AUTOSAR XML (schema 4.0)
standard types defined: float32, float64, sint16, sint32, sint8, uint16, uint32, uint8, void, boolean
package /ImplDataTypes
  5 x impl type, all with category=TYPE_REFERENCE, type-emitter=RTE:
    MultiStateBtnType: implementation-data-type=uint8
    SeatCtrlData_Height: implementation-data-type=uint8
    SeatCtrlData_Incline: implementation-data-type=void
    SeatCtrlData_Slide: implementation-data-type=uint8
    StepMotorStepType: implementation-data-type=uint8
package /MappingSets
  data type mapping set MappingSet
package /PortInterfaces/ClientServer
  client server interface CsIf_StepMotor
    operation Opr_Move
      arg step: type=StepMotorStepType, direction=IN
package /PortInterfaces/SenderReceiver
  sender receiver interface SrIf_SeatCtrlBtns
    data DE_HeightBtnState: type=MultiStateBtnType
    data DE_InclineBtnState: type=MultiStateBtnType
    data DE_SlideBtnState: type=MultiStateBtnType
  sender receiver interface SrIf_SeatCtrlData
    data DE_Height: type=SeatCtrlData_Height
    data DE_Incline: type=SeatCtrlData_Incline
    data DE_Slide: type=SeatCtrlData_Slide
package /SoftwareComponents
  5 x swc implementation, all with programming-language=C, sw-version=1.0.0, vendor-id=255:
    Impl_SWC_HMI: behavior=Ibhv_SWC_HMI
      code-descriptors:
        code Code: artifact-descriptors=autosar-engineering-object={short-label=SWC.c, category=SWSRC}
      resource consumption ResourceConsumption
    Impl_SWC_HeightMotor: behavior=Ibhv_SWC_HeightMotor
      code-descriptors:
        code Code: artifact-descriptors=autosar-engineering-object={short-label=SWC.c, category=SWSRC}
      resource consumption ResourceConsumption
    Impl_SWC_InclineMotor: behavior=Ibhv_SWC_InclineMotor
      code-descriptors:
        code Code: artifact-descriptors=autosar-engineering-object={short-label=SWC.c, category=SWSRC}
      resource consumption ResourceConsumption
    Impl_SWC_Seatmanager: behavior=Ibhv_SWC_Seatmanager
      code-descriptors:
        code Code: artifact-descriptors=autosar-engineering-object={short-label=SWC.c, category=SWSRC}
      resource consumption ResourceConsumption
    Impl_SWC_SlideMotor: behavior=Ibhv_SWC_SlideMotor
      code-descriptors:
        code Code: artifact-descriptors=autosar-engineering-object={short-label=SWC.c, category=SWSRC}
      resource consumption ResourceConsumption
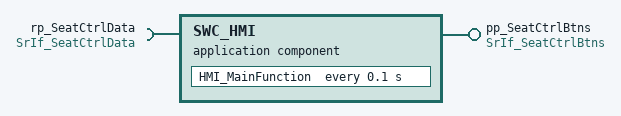
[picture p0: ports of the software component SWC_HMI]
  application sw component type SWC_HMI
    provide port pp_SeatCtrlBtns: provided-interface=SrIf_SeatCtrlBtns
    require port rp_SeatCtrlData: required-interface=SrIf_SeatCtrlData
    behavior Ibhv_SWC_HMI: data-type-mapping=MappingSet, handle-termination-and-restart=NO-SUPPORT
      timing event TE_HMI_MainFunction_100ms: start-on-event=HMI_MainFunction, period=0.1
      runnable HMI_MainFunction
        data-receive-point-by-arguments:
          access DRP_rp_SeatCtrlData_DE_Height: accessed-variable=rp_SeatCtrlData.DE_Height
          access DRP_rp_SeatCtrlData_DE_Incline: accessed-variable=rp_SeatCtrlData.DE_Incline
          access DRP_rp_SeatCtrlData_DE_Slide: accessed-variable=rp_SeatCtrlData.DE_Slide
        data-send-points:
          access DSP_pp_SeatCtrlBtns_DE_HeightBtnState: accessed-variable=pp_SeatCtrlBtns.DE_HeightBtnState
          access DSP_pp_SeatCtrlBtns_DE_InclineBtnState: accessed-variable=pp_SeatCtrlBtns.DE_InclineBtnState
          access DSP_pp_SeatCtrlBtns_DE_SlideBtnState: accessed-variable=pp_SeatCtrlBtns.DE_SlideBtnState
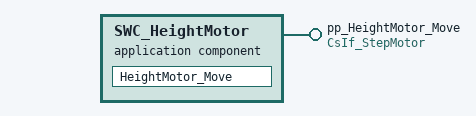
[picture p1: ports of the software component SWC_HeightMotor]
  application sw component type SWC_HeightMotor
    provide port pp_HeightMotor_Move: provided-interface=CsIf_StepMotor
    behavior Ibhv_SWC_HeightMotor: data-type-mapping=MappingSet, handle-termination-and-restart=NO-SUPPORT
      operation invoked event OIE_pp_HeightMotor_Move_Opr_Move: start-on-event=HeightMotor_Move, operation=pp_HeightMotor_Move.Opr_Move
      runnable HeightMotor_Move
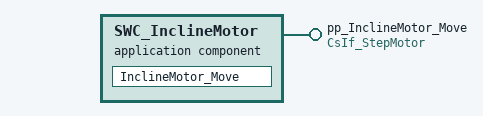
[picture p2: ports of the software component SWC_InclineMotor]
  application sw component type SWC_InclineMotor
    provide port pp_InclineMotor_Move: provided-interface=CsIf_StepMotor
    behavior Ibhv_SWC_InclineMotor: data-type-mapping=MappingSet, handle-termination-and-restart=NO-SUPPORT
      operation invoked event OIE_pp_InclineMotor_Move_Opr_Move: start-on-event=InclineMotor_Move, operation=pp_InclineMotor_Move.Opr_Move
      runnable InclineMotor_Move
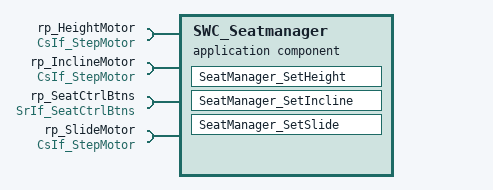
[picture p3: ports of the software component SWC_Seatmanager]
  application sw component type SWC_Seatmanager
    4 x require port:
      rp_HeightMotor: required-interface=CsIf_StepMotor
      rp_InclineMotor: required-interface=CsIf_StepMotor
      rp_SeatCtrlBtns: required-interface=SrIf_SeatCtrlBtns
      rp_SlideMotor: required-interface=CsIf_StepMotor
    behavior Ibhv_SWC_Seatmanager: data-type-mapping=MappingSet, handle-termination-and-restart=NO-SUPPORT
      data received event DRE_rp_SeatCtrlBtns_DE_HeightBtnState: start-on-event=SeatManager_SetHeight, data=rp_SeatCtrlBtns.DE_HeightBtnState
      data received event DRE_rp_SeatCtrlBtns_DE_InclineBtnState: start-on-event=SeatManager_SetIncline, data=rp_SeatCtrlBtns.DE_InclineBtnState
      data received event DRE_rp_SeatCtrlBtns_DE_SlideBtnState: start-on-event=SeatManager_SetSlide, data=rp_SeatCtrlBtns.DE_SlideBtnState
      runnable SeatManager_SetHeight
        data-receive-point-by-arguments:
          access DRP_rp_SeatCtrlBtns_DE_HeightBtnState: accessed-variable=rp_SeatCtrlBtns.DE_HeightBtnState
        sync call SCP_rp_HeightMotor_Opr_Move: operation=rp_HeightMotor.Opr_Move, timeout=0.0
      runnable SeatManager_SetIncline
        data-receive-point-by-arguments:
          access DRP_rp_SeatCtrlBtns_DE_InclineBtnState: accessed-variable=rp_SeatCtrlBtns.DE_InclineBtnState
        sync call SCP_rp_InclineMotor_Opr_Move: operation=rp_InclineMotor.Opr_Move, timeout=0.0
      runnable SeatManager_SetSlide
        data-receive-point-by-arguments:
          access DRP_rp_SeatCtrlBtns_DE_SlideBtnState: accessed-variable=rp_SeatCtrlBtns.DE_SlideBtnState
        sync call SCP_rp_SlideMotor_Opr_Move: operation=rp_SlideMotor.Opr_Move, timeout=0.0
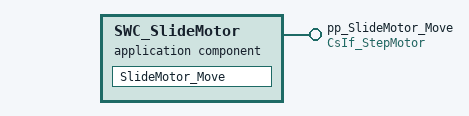
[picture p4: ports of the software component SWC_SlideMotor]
  application sw component type SWC_SlideMotor
    provide port pp_SlideMotor_Move: provided-interface=CsIf_StepMotor
    behavior Ibhv_SWC_SlideMotor: data-type-mapping=MappingSet, handle-termination-and-restart=NO-SUPPORT
      operation invoked event OIE_pp_SlideMotor_Move_Opr_Move: start-on-event=SlideMotor_Move, operation=pp_SlideMotor_Move.Opr_Move
      runnable SlideMotor_Move
package /Compositions
  composition sw component type SenderReceiver_Task2Composition
    5 x component:
      SWC_HMI: type=SWC_HMI
      SWC_HeightMotor: type=SWC_HeightMotor
      SWC_InclineMotor: type=SWC_InclineMotor
      SWC_Seatmanager: type=SWC_Seatmanager
      SWC_SlideMotor: type=SWC_SlideMotor
    connect SWC_HMI.pp_SeatCtrlBtns -> SWC_Seatmanager.rp_SeatCtrlBtns
    connect SWC_HeightMotor.pp_HeightMotor_Move -> SWC_Seatmanager.rp_HeightMotor
    connect SWC_InclineMotor.pp_InclineMotor_Move -> SWC_Seatmanager.rp_InclineMotor
    connect SWC_SlideMotor.pp_SlideMotor_Move -> SWC_Seatmanager.rp_SlideMotor
